# WKUP_UART0 register map
Vendor: Texas Instruments
Peripheral module from a debugger description file (folder J722S).
Registers are 32-bit, access per field, reset 0x0 unless marked. A register's access mark holds for its fields unless they carry their own. Offsets are as the file gives them; lines under a group give offsets from that group; [hi:lo] are bit positions; {n}, {i} and the like mark numbered series; 'fields as' and 'values as' point back to an identical list; <NAME> marks a mode.

## WKUP_UART0
0x00 MEM_DLL rw — Divisor Latches Low Register
  [7:0] CLOCK_LSB — Used to store the 8-bit LSB divisor value
0x00 MEM_RHR ro — The receiver section consists of the receiver holding register (RHR) and the receiver shift register. The RHR is actually a 64-byte FIFO. The receiver shift register receives serial data from RX input. The data is converted to parallel data and moved to the RHR. If the FIFO is disabled location zero of the FIFO is used to store the single data character. Note: If an overflow occurs the data in the RHR is not overwritten.
  [7:0] RHR — Receive holding register
0x00 MEM_THR — The transmitter section consists of the transmit holding register (THR) and the transmit shift register. The transmit holding register is actually a 64-byte FIFO. The LH writes data to the THR. The data is placed into the transmit shift register where it is shifted out serially on the TX output. If the FIFO is disabled location zero of the FIFO is used to store the data.
  [7:0] THR wo — TRANSMIT HOLDING REGISTER
0x04 MEM_DLH rw — Divisor Latches High Register
  [7:0] CLOCK_MSB — Used to store the 8-bit MSB divisor value
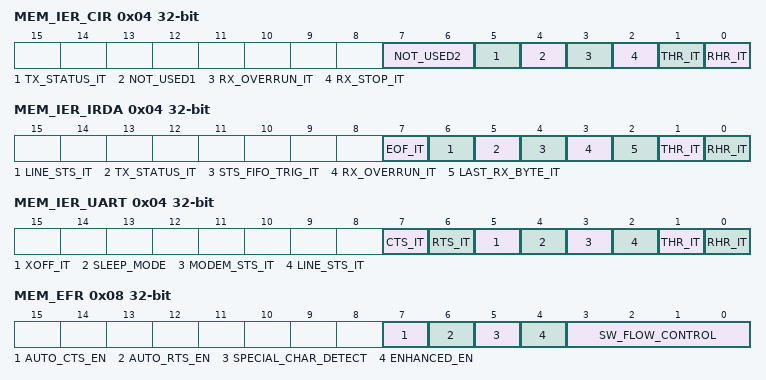
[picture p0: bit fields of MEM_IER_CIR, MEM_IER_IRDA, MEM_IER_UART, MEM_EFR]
0x04 MEM_IER_CIR rw — The interrupt enable register (IER) can be programmed to enable/disable any interrupt. There are 6 types of interrupt in these modes, TX status, status FIFO interrupt, RX overrun, last byte in RX FIFO, THR interrupt and RHR interrupt and they can be enabled/disabled individually.
  [7:6] NOT_USED2, [5] TX_STATUS_IT, [4] NOT_USED1, [3] RX_OVERRUN_IT, [2] RX_STOP_IT, [1] THR_IT, [0] RHR_IT
0x04 MEM_IER_IRDA rw — The interrupt enable register (IER) can be programmed to enable/disable any interrupt. There are 8 types of interrupt in these modes, received EOF, LSR interrupt, TX status, status FIFO interrupt, RX overrun, last byte in RX FIFO, THR interrupt and RHR interrupt and they can be enabled/disabled individually.
  [7] EOF_IT, [6] LINE_STS_IT, [5] TX_STATUS_IT, [4] STS_FIFO_TRIG_IT, [3] RX_OVERRUN_IT, [2] LAST_RX_BYTE_IT, [1] THR_IT, [0] RHR_IT
0x04 MEM_IER_UART — The interrupt enable register (IER) can be programmed to enable/disable any interrupt. There are seven types of interrupt in this mode: receiver error, RHR interrupt, THR interrupt, XOFF received and CTS*/RTS* change of state from low to high. Each interrupt can be enabled/disabled individually. There is also a sleep mode enable bit.
  [7] CTS_IT rw, [6] RTS_IT rw, [5] XOFF_IT rw, [4] SLEEP_MODE rw, [3] MODEM_STS_IT rw, [2] LINE_STS_IT rw, [1] THR_IT rw, [0] RHR_IT rw
0x08 MEM_EFR rw — Enhanced Feature Register
  [7] AUTO_CTS_EN — Auto-CTS enable bit. 0: Normal operation. 1: Auto-CTS flow control is enabled i.e. transmission is halted when the CTS* pin is high (inactive).
  [6] AUTO_RTS_EN — Auto-RTS enable bit. 0: Normal operation. 1: Auto- RTS flow control is enabled i.e. RTS* pin goes high (inactive) when the receiver FIFO HALT trigger level, TCR[3:0], is reached, and goes low (active) when the receiver FIFO RESTORE transmission trigger level is reached.
  [5] SPECIAL_CHAR_DETECT — 0: Normal operation. 1: Special character detect enable. Received data is compared with XOFF2 data. If a match occurs the received data is transferred to RX FIFO and IIR bit 4 is set to 1 to indicate a special character has been detected.
  [4] ENHANCED_EN — Enhanced functions write enable bit. 0: Disables writing to IER bits 4-7, FCR bits 4-5, and MCR bits 5-7. 1: Enables writing to IER bits 4-7, FCR bits 4-5, and MCR bits 5-7.
  [3:0] SW_FLOW_CONTROL — Combinations of Software flow control can be selected by programming bit 3 - bit 0. See Software Flow Control Options
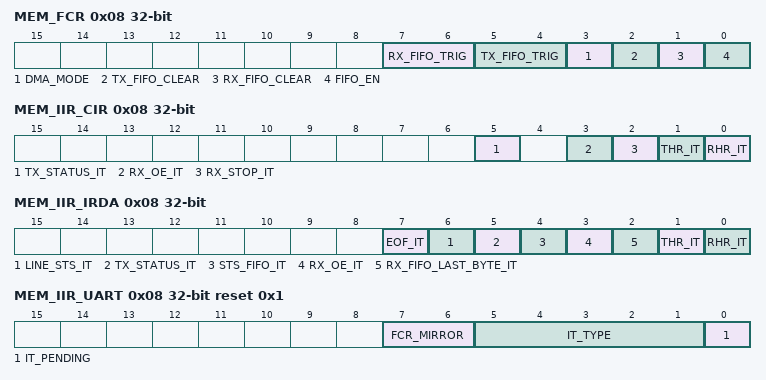
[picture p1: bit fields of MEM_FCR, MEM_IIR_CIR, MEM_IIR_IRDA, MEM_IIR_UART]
0x08 MEM_FCR — Notes: Bits 4 and 5 can only be written to when EFR[4] = 1 Bits 0 to 3 can be changed only when the baud clock is not running (DLL and DLH set to 0) See Table 31 for FCR[5:4] setting restriction when SCR[6]=1 See Table 32 for FCR[7:6] setting restriction when SCR[7]=1
  [7:6] RX_FIFO_TRIG wo — Sets the trigger level for the RX FIFO: If SCR[7] = 0 and TLR[7:4] = 0000: 00: 8 characters 01: 16 characters 10: 56 characters 11: 60 characters If SCR[7] = 0 and TLR[7:4] != 0000, RX_FIFO_TRIG is not considered. If SCR[7]=1, RX_FIFO_TRIG is 2 LSB of the trigger level [1-63 on 6 bits] with the granularity 1.
  [5:4] TX_FIFO_TRIG wo — Sets the trigger level for the TX FIFO: If SCR[6] = 0 and TLR[3:0] = 0000: 00: 8 spaces 01: 16 spaces 10: 32 spaces 11: 56 spaces If SCR[6] = 0 and TLR[3:0] != 0000, TX_FIFO_TRIG is not considered. If SCR[6]=1, TX_FIFO_TRIG is 2 LSB of the trigger level [1-63 on 6 bits] with the granularity 1
  [3] DMA_MODE wo — This register is considered if SCR[0] = 0.
  [2] TX_FIFO_CLEAR wo
  [1] RX_FIFO_CLEAR wo
  [0] FIFO_EN wo
0x08 MEM_IIR_CIR ro — The IIR is a read-only register, which provides the source of the interrupt in a prioritized manner.
  [5] TX_STATUS_IT, [3] RX_OE_IT, [2] RX_STOP_IT, [1] THR_IT, [0] RHR_IT
0x08 MEM_IIR_IRDA ro — The IIR is a read-only register, which provides the source of the interrupt in a prioritized manner.
  [7] EOF_IT, [6] LINE_STS_IT, [5] TX_STATUS_IT, [4] STS_FIFO_IT, [3] RX_OE_IT, [2] RX_FIFO_LAST_BYTE_IT, [1] THR_IT, [0] RHR_IT
0x08 MEM_IIR_UART ro reset 0x1 — The IIR is a read-only register, which provides the source of the interrupt in a prioritized manner.
  [7:6] FCR_MIRROR — Mirror the contents of FCR[0] on both bits.
  [5:1] IT_TYPE
  [0] IT_PENDING
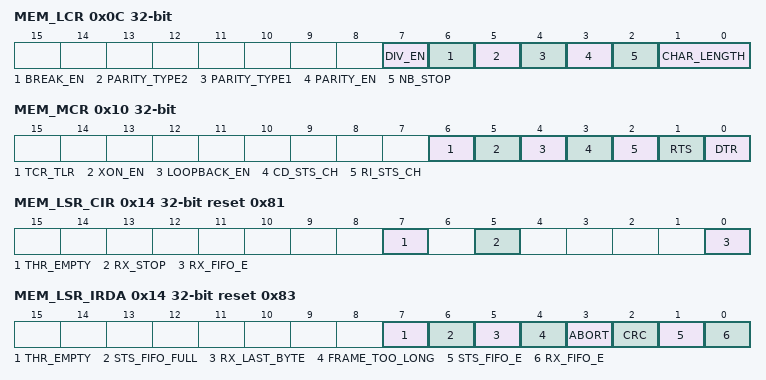
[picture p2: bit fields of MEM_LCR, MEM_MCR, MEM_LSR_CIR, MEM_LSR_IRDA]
0x0C MEM_LCR — LCR[6:0] define parameters of the transmission and reception. Note: As soon as LCR[6] is set to 1, the TX line is forced to 0 and remains in this state as long as LCR[6] = 1.
  [7] DIV_EN rw
  [6] BREAK_EN rw — Break control bit.
  [5] PARITY_TYPE2 rw — Selects the forced parity format [if LCR[3] = 1]. If LCR[5] = 1 and LCR[4] = 0, the parity bit is forced to 1 in the transmitted and received data. If LCR[5] = 1 and LCR[4] = 1, the parity bit is forced to 0 in the transmitted and received data.
  [4] PARITY_TYPE1 rw
  [3] PARITY_EN rw
  [2] NB_STOP rw — Specifies the number of stop bits:
  [1:0] CHAR_LENGTH rw — Specifies the word length to be transmitted or received.
0x10 MEM_MCR — MCR[3:0] controls the interface with the modem, data set or peripheral device that is emulating the modem.
  [6] TCR_TLR rw
  [5] XON_EN rw
  [4] LOOPBACK_EN rw
  [3] CD_STS_CH rw
  [2] RI_STS_CH rw
  [1] RTS rw — In loop back controls MSR[4]. If auto-RTS is enabled the RTS* output is controlled by hardware flow control.
  [0] DTR rw
0x10 MEM_XON1_ADDR1 rw — XON1/ADDR1 Register
  [7:0] XON_WORD1 — Used to store the 8-bit XON1 character in UART modes and ADDR1 address 1 for IrDA modes.
0x14 MEM_LSR_CIR ro reset 0x81
  [7] THR_EMPTY
  [5] RX_STOP — The RX_STOP is generated based on the value set in the BOF Length register (EBLR). It is cleared on a single read of the LSR register
  [0] RX_FIFO_E
0x14 MEM_LSR_IRDA ro reset 0x83
  [7] THR_EMPTY, [6] STS_FIFO_FULL, [5] RX_LAST_BYTE, [4] FRAME_TOO_LONG, [3] ABORT, [2] CRC, [1] STS_FIFO_E, [0] RX_FIFO_E
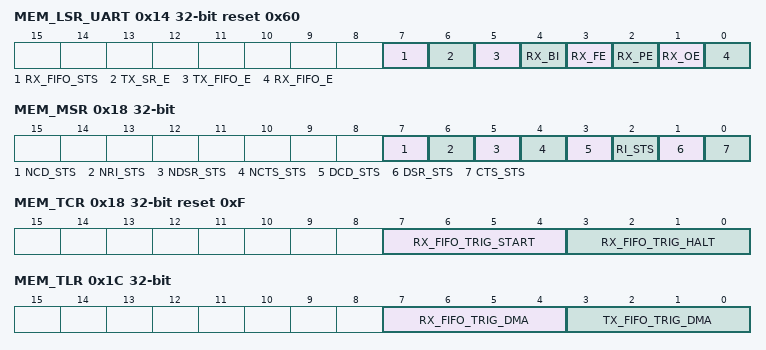
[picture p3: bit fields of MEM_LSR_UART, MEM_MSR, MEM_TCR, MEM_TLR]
0x14 MEM_LSR_UART ro reset 0x60
  [7] RX_FIFO_STS, [6] TX_SR_E, [5] TX_FIFO_E, [4] RX_BI, [3] RX_FE, [2] RX_PE, [1] RX_OE, [0] RX_FIFO_E
0x14 MEM_XON2_ADDR2 rw — XON2/ADDR2 Register
  [7:0] XON_WORD2 — Used to store the 8-bit XON2 character in UART modes and ADDR2 address 2 for IrDA modes.
0x18 MEM_MSR ro — This register provides information about the current state of the control lines from the modem, data set or peripheral device to the LH. It also indicates when a control input from the modem changes state.
  [7] NCD_STS — This bit is the complement of the DCD* input. In loop-back mode it is equivalent to MCR[3]
  [6] NRI_STS — This bit is the complement of the RI* input. In loop-back mode it is equivalent to MCR[2]
  [5] NDSR_STS — This bit is the complement of the DSR* input. In loop-back mode, it is equivalent to MCR[0]
  [4] NCTS_STS — This bit is the complement of the CTS* input. In loop-back mode it is equivalent to MCR[1]
  [3] DCD_STS — Indicates that DCD* input [or MCR[3] in loop back] has changed. Cleared on a read.
  [2] RI_STS — Indicates that RI* input [or MCR[2] in loop back] has changed state from low to high. Cleared on a read.
  [1] DSR_STS
  [0] CTS_STS
0x18 MEM_TCR rw reset 0xF — Transmission Control Register
  [7:4] RX_FIFO_TRIG_START — RX FIFO trigger level to RESTORE transmission (0 - 60)
  [3:0] RX_FIFO_TRIG_HALT — RX FIFO trigger level to HALT transmission (0 - 60)
0x18 MEM_XOFF1 rw — XOFF1 Register
  [7:0] XOFF_WORD1 — Used to store the 8-bit XOFF1 character in used in UART modes.
0x1C MEM_SPR — This read/write register does not control the module in anyway. It is intended as a scratchpad register to be used by the programmer to hold temporary data.
  [7:0] SPR_WORD rw — Scratchpad register
0x1C MEM_TLR rw — Trigger Level Register
  [7:4] RX_FIFO_TRIG_DMA — Receive FIFO trigger level
  [3:0] TX_FIFO_TRIG_DMA — Transmit FIFO trigger level
0x1C MEM_XOFF2 rw — XOFF2 Register
  [7:0] XOFF_WORD2 — Used to store the 8-bit XOFF2 character in used in UART modes.
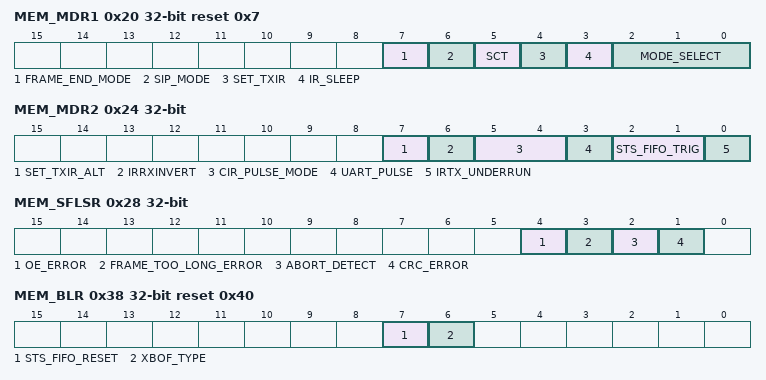
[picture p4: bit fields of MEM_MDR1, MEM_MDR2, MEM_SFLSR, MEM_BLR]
0x20 MEM_MDR1 reset 0x7 — The mode of operation can be programmed by writing to MDR1[2:0] and therefore the MDR1 must be programmed on start-up after configuration of the configuration registers (DLL, DLH, LCR). The value of MDR1[2:0] must not be changed again during normal operation. Note: If the module is disabled by setting the MODE_SELECT field to
  [7] FRAME_END_MODE rw — IrDA mode only.
  [6] SIP_MODE rw — MIR/FIR modes only.
  [5] SCT rw — Store and control the transmission
  [4] SET_TXIR rw — Used to configure the infrared transceiver.
  [3] IR_SLEEP rw
  [2:0] MODE_SELECT rw
0x24 MEM_MDR2 — IR-IrDA and IR-CIR modes only. MDR2[0] describes the status of the interrupt in IIR[5]. The IRTX_UNDERRUN bit should be read after an IIR[5] TX_STATUS_IT interrupt has occurred. The bits [2:1] of this register sets the trigger level for the frame status FIFO (8 entries) and must be programmed before the mode is programmed in MDR1[2:0]. Note: The MDR2[6] gives the flexibility to invert the RX pin inside the UART module to ensure that the protocol at the input of the transceiver module has the same polarity at module level. By default, the RX pin is inverted because most of transceiver invert the IR receive pin.
  [7] SET_TXIR_ALT rw — Provide alternate functionnality for MDR1[4] [SET_TXIR]
  [6] IRRXINVERT rw — Only for IR mode [IRDA & CIR]Invert RX pin inside the module before the voting or sampling system logic of the infra red block. This will not affect the RX path in UART Modem modes.
  [5:4] CIR_PULSE_MODE rw — CIR Pulse modulation definition. It defines high level of the pulse width associated with a digit:
  [3] UART_PULSE rw — UART mode only. Used to allow pulse shaping in UART mode.
  [2:1] STS_FIFO_TRIG rw — Only for IR-IRDA mode. Frame Status FIFO Threshold select:
  [0] IRTX_UNDERRUN ro — IRDA Transmission status interrupt.When the IIR[5] interrupt occurs, the meaning of the interrupt is :
0x28 MEM_SFLSR ro — IrDA modes only. Reading this register effectively reads frame status information from the status FIFO (this register doesn't physically exist). Reading this register will increment the status FIFO read pointer (SFREGL and SFREGH must be read first).
  [4] OE_ERROR, [3] FRAME_TOO_LONG_ERROR, [2] ABORT_DETECT, [1] CRC_ERROR
0x28 MEM_TXFLL — IrDA modes only. The registers TXFLL and TXFLH hold the 13-bit transmit frame length (expressed in bytes). TXFLL holds the least significant bits and TXFLH holds the most significant bits. The frame length value is used if the frame length method of frame closing is used.
  [7:0] TXFLL wo — LSB register used to specify the frame length
0x2C MEM_RESUME ro — IR-IrDA and IR-CIR modes only. This register is used to clear internal flags, which halt transmission/reception when an underrun/overrun error occurs. Reading this register resumes the halted operation. This register does not physically exist and reads always as 0x00.
  [7:0] RESUME — Dummy read to restart the TX or RX
0x2C MEM_TXFLH — IrDA modes only. The registers TXFLL and TXFLH hold the 13-bit transmit frame length (expressed in bytes). TXFLL holds the least significant bits and TXFLH holds the most significant bits. The frame length value is used if the frame length method of frame closing is used.
  [4:0] TXFLH wo — MSB register used to specify the frame length
0x30 MEM_RXFLL — IrDA modes only. The registers RXFLL and RXFLH hold the 12-bit receive maximum frame length. RXFLL holds the least significant bits and RXFLH holds the most significant bits. If the intended maximum receive frame length is n bytes, then program RXFLL and RXFLH to be n + 3 in SIR or MIR modes and n + 6 in FIR mode (+3 and +6 are due to frame format with CRC and stop flag; there are two bytes associated with the FIR stop flag).
  [7:0] RXFLL wo — LSB register used to specify the frame length in reception
0x30 MEM_SFREGL ro — IrDA modes only. The frame lengths of received frames are written into the status FIFO. This information can be read by reading the SFREGL and SFREGH registers (i.e. these registers do not physically exist). The least significant bits are read from SFREGL and the most significant bits are read from SFREGH. Reading these registers does not alter the status FIFO read pointer. These registers should be read before the pointer is incremented by reading the SFLSR.
  [7:0] SFREGL — LSB part of the frame length
0x34 MEM_RXFLH — IrDA modes only. The registers RXFLL and RXFLH hold the 12-bit receive maximum frame length. RXFLL holds the least significant bits and RXFLH holds the most significant bits. If the intended maximum receive frame length is n bytes, then program RXFLL and RXFLH to be n + 3 in SIR or MIR modes and n + 6 in FIR mode (+3 and +6 are due to frame format with CRC and stop flag; there are two bytes associated with the FIR stop flag).
  [3:0] RXFLH wo — MSB register used to specify the frame length in reception
0x34 MEM_SFREGH ro — IrDA modes only. The frame lengths of received frames are written into the status FIFO. This information can be read by reading the SFREGL and SFREGH registers (i.e. these registers do not physically exist). The least significant bits are read from SFREGL and the most significant bits are read from SFREGH. Reading these registers does not alter the status FIFO read pointer. These registers should be read before the pointer is incremented by reading the SFLSR.
  [3:0] SFREGH — MSB part of the frame length
0x38 MEM_BLR access not given reset 0x40 — IrDA modes only. Note that BLR[6] is used to select whether 0xC0 or 0xFF start patterns are to be used, when multiple start flags are required in SIR Mode. If only one start flag is required, this will always be 0xC0. If n start flags are required, then either (n-1) 0xC0 or (n-1) 0xFF flags are sent, followed by a single 0xC0 flag (immediately preceding the first data byte).
  [7] STS_FIFO_RESET — Status FIFO reset. This bit is self-clearing (access R/W1TS)
  [6] XBOF_TYPE rw — SIR xBOF select.
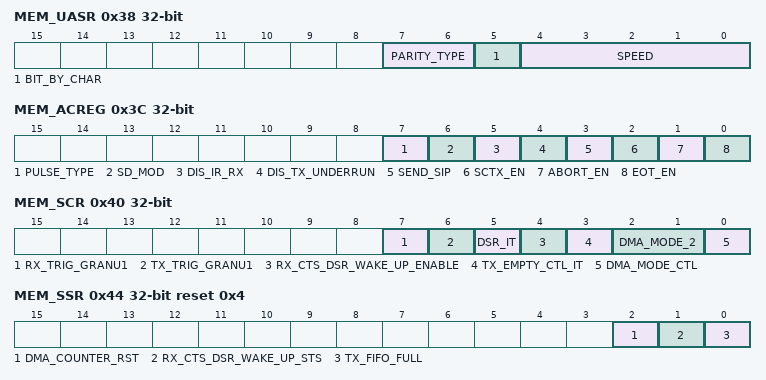
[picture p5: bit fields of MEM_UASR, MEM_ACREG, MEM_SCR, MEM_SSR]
0x38 MEM_UASR ro — UART Autobauding Status Register
  [7:6] PARITY_TYPE — 00 => No Parity identified. 01 => Parity space. 10 => Even Parity. 11 => Odd Parity
  [5] BIT_BY_CHAR — 0 => 7 bits character identified. 1 => 8 bits character identified
  [4:0] SPEED — Used to report the speed identified. 00000 => No speed identified. 00001 => 115200 bauds. 00010 => 57600 bauds. 00011 => 38400 bauds. 00100 => 28800 bauds. 00101 => 19200 bauds. 00110 => 14400 bauds. 00111 => 9600 bauds. 01000 => 4800 bauds. 01001 => 2400 bauds. 01010 => 1200 bauds
0x3C MEM_ACREG access not given — IR-IrDA and IR-CIR modes only.
  [7] PULSE_TYPE rw — SIR pulse width select:
  [6] SD_MOD rw — Primary output used to configure transceivers. Connected to the SD/MODE input pin of IrDA transceivers.
  [5] DIS_IR_RX rw
  [4] DIS_TX_UNDERRUN rw — It is recommended to disable TX FIFO underrun capability by masking corresponding underrun interrupt. When disabling underrun by setting ACREG[4]=1, garbage data is sent over TX line.
  [3] SEND_SIP — MIR/FIR Modes only.Send Serial Infrared Interaction Pulse [SIP] If this bit is set during a MIR/FIR transmission, the SIP will be send at the end of it.This bit automatically gets cleared at the end of the SIP transmission. (access R/W1TS)
  [2] SCTX_EN — Store and controlled TX start. When MDR1[5] = 1 and the LH writes 1 to this bit the TX state machine starts frame transmission. This bit is self-clearing. (access R/W1TS)
  [1] ABORT_EN rw — Frame Abort. The LH can intentionally abort transmission of a frame by writing 1 to this bit. Neither the end flag nor the CRC bits are appended to the frame. If transmit FIFO is not empty and MDR1[5]=1, UART IrDA will start a new transfer with data of previous frame as soon as abort frame has been sent. Therefore, TX FIFO must be reset before sending an abort frame.
  [0] EOT_EN — EOT [end of transmission] bit. The LH writes 1 to this bit just before it writes the last byte to the TX FIFO in set-EOT bit frame closing method. This bit automatically gets cleared when the LH writes to the THR [TX FIFO]. (access R/W1TS)
0x40 MEM_SCR — Note: Bit 4 enables the wake-up interrupt, but this interrupt is not mapped into the IIR register. Therefore, when an interrupt occurs and there is no interrupt pending in the IIR register, the SSR[1] bit must be checked. To clear the wake-up interrupt, bit SCR[4] must be reset to 0.
  [7] RX_TRIG_GRANU1 rw
  [6] TX_TRIG_GRANU1 rw
  [5] DSR_IT rw
  [4] RX_CTS_DSR_WAKE_UP_ENABLE rw
  [3] TX_EMPTY_CTL_IT rw
  [2:1] DMA_MODE_2 rw — Used to specify the DMA mode valid if SCR[0] = 1
  [0] DMA_MODE_CTL rw
0x44 MEM_SSR reset 0x4 — Note: Bit 1 is reset only when SCR[4] is reset to 0.
  [2] DMA_COUNTER_RST rw, [1] RX_CTS_DSR_WAKE_UP_STS ro, [0] TX_FIFO_FULL ro
0x48 MEM_EBLR — IR-IrDA and IR-CIR modes only. In IR-IrDA SIR operation, this register specifies the number of BOF + xBOFs to transmit. Value set into this register must take into account the BOF character, therefore to only sent one BOF with no XBOF this register must be set to 1. To send one BOF with N XBOF this register must be set to N+1. Furthermore, the value 0 will send 1 BOF plus 255 XBOF. In IR-IrDA MIR mode, this register specifies the number of additional start flags (MIR protocol mandates a minimum of 2 start flags). In IR-CIR mode, this register specifies the number of consecutive zeros to be received before generating the RX_STOP interrupt (IIR[2]). All the received zeros are stored in the RX FIFO. When the register is set to 0, this feature is de-activated and always in reception state which can be disabled by setting the ACREG[5] to
  [7:0] EBLR rw — IR-IRDA mode: This register allows to define up to 176 xBOFs, the maximum required by IrDA specification. IR-CIR mode: This register specifies the number of consecutive zeros to be received before generating the RX_STOP interrupt [IIR[2]]. 0x00: feature disabled. 0x01: generate RX_STOP interrupt after receiving one zero bit. ... 0xFF: generate RX_STOP interrupt after receiving 255 zero bits.
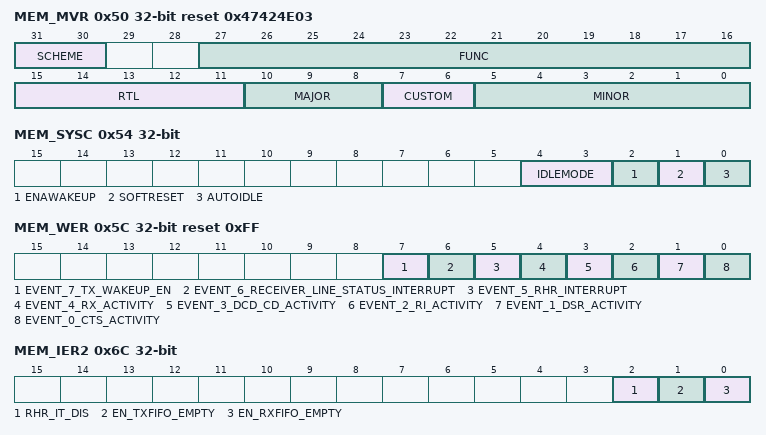
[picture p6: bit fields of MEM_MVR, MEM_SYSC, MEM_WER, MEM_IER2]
0x50 MEM_MVR ro reset 0x47424E03 — The reset value is fixed by hardware and corresponds to the RTL revision of this module. A reset has no effect on the value returned Notes: UART / IRDA SIR only module is revision 1.x (WMU_012_1 specification). UART / IRDA with SIR, MIR and FIR support is revision 2.x (WMU_012_2 specification). UART / IRDA with SIR, MIR and FIR / CIR support is revision 3.x (this specification). For example: MVR = 0x30 => Version 3.0 MVR = 0x38 => Version 3.8
  [31:30] SCHEME — Scheme revision number of module
  [27:16] FUNC — Function revision number of module
  [15:11] RTL — Rtl revision number of module
  [10:8] MAJOR — Major revision number of the module.
  [7:6] CUSTOM — Custom revision number of the module.
  [5:0] MINOR — Minor revision number of the module.
0x54 MEM_SYSC — The auto idle bit controls a power saving technique to reduce the logic power consumption of the OCP interface. That is to say when the feature is enabled, the clock will be gated off until an OCP command for this device has been detected. When the software reset bit is set high it causes a full device reset.
  [4:3] IDLEMODE rw — POWER MANAGEMENT REQ/ACK CONTROL REF: OCP DESIGN GUIDELINES VERSION 1.1
  [2] ENAWAKEUP rw — WAKE UP FEATURE CONTROL
  [1] SOFTRESET wo — Software reset. Set this bit to 1 to trigger a module reset. This bit is automatically reset by the hardware. During reads it always returns a 0.
  [0] AUTOIDLE rw — Internal OCP clock gating strategy
0x58 MEM_SYSS ro
  [0] RESETDONE — Internal Reset Monitoring
0x5C MEM_WER reset 0xFF — The UART wakeup enable register is used to mask and unmask a UART event that would subsequently notify the system. The events are any activity in the logic that could cause an interrupt and/ or an activity that would require the system to wakeup. It should be noted that even if the wakeup is disabled for certain events, if these events are also an interrupt to the UART, then the UART will still register the interrupt as such.
  [7] EVENT_7_TX_WAKEUP_EN rw, [6] EVENT_6_RECEIVER_LINE_STATUS_INTERRUPT rw, [5] EVENT_5_RHR_INTERRUPT rw, [4] EVENT_4_RX_ACTIVITY rw, [3] EVENT_3_DCD_CD_ACTIVITY rw, [2] EVENT_2_RI_ACTIVITY rw, [1] EVENT_1_DSR_ACTIVITY rw, [0] EVENT_0_CTS_ACTIVITY rw
0x60 MEM_CFPS reset 0x69 — Since the Consumer IR works at modulation rates of 30 56.8 KHz, the 48 MHz clock must be pre scaled before the clock can drive the IR logic. This register sets the divisor rate to give a range to accommodate the remote control requirements in BAUD multiples of 12x. The value of the CFPS at reset is 0105 decimal which equates to a 38.1 KHz output from starting conditions. The 48 MHz carrier is prescaled by the CFPS which is then divided by the 12x BAUD multiple.
  [7:0] CFPS rw — System clock frequency prescaler at [12x multiple]. Examples for CFPS values are given in the table below. Target Freq [KHz] CFPS [decimal] Actual Freq[KHz] 30 133 30.08 32.75 122 32.79 36 111 36.04 36.7 109 36.69 38* 105 38.1 40 100 40 56.8 70 57.14 * configured at reset to this value Note: CFPS = 0 is not supported.
0x64 MEM_RXFIFO_LVL ro — Level of the RX FIFO
  [7:0] RXFIFO_LVL
0x68 MEM_TXFIFO_LVL ro — Level of the TX FIFO
  [7:0] TXFIFO_LVL
0x6C MEM_IER2 — Enables RX/TX FIFOs empty corresponding interrupts.
  [2] RHR_IT_DIS rw
  [1] EN_TXFIFO_EMPTY rw — Enables[1]/DISABLES[00 EN_TXFIFO_EMPTY interrupt.
  [0] EN_RXFIFO_EMPTY rw — Enables[1]/disables[0] EN_RXFIFO_EMPTY interrupt.
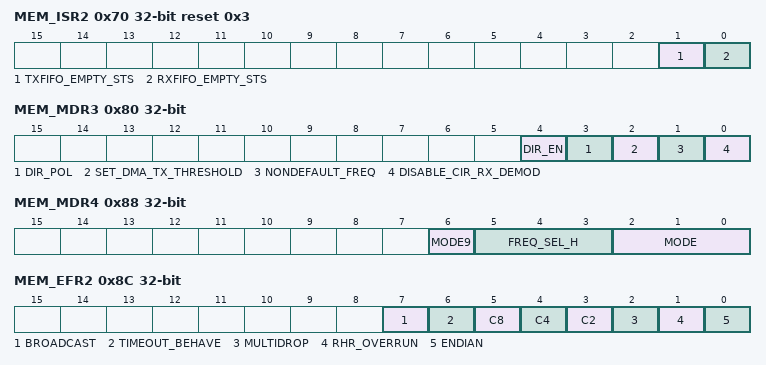
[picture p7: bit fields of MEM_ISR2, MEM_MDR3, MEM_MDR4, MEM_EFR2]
0x70 MEM_ISR2 access not given reset 0x3 — Status of RX/TX FIFOs empty corresponding interrupts.
  [1] TXFIFO_EMPTY_STS — TXFIFO interrupt pending (access R/W1TC)
  [0] RXFIFO_EMPTY_STS — RXFIFO interrupt pending (access R/W1TC)
0x74 MEM_FREQ_SEL rw reset 0x1A — Sample per bit value selector
  [7:0] FREQ_SEL — Sets the sample per bit if non default frequency is used. MDR3[1] must be set to 1 after this value is set. Must be equal or higher then 6.
0x78 MEM_ABAUD_1ST_CHAR ro — Unused
0x7C MEM_BAUD_2ND_CHAR ro — Unused
0x80 MEM_MDR3 — Mode definition register 3.
  [4] DIR_EN rw — RS-485 External Transceiver Direction Enable
  [3] DIR_POL rw — RS-485 External Transceiver Direction Polarity. 0 => TX: RTS=0, RX: RTS=1. 1 => TX: RTS=1, RX: RTS=0
  [2] SET_DMA_TX_THRESHOLD rw — Enable to set different TX DMA threshold then 64-trigger [usage of new register TX_DNA_THRESHOLD]
  [1] NONDEFAULT_FREQ rw — Enables[1]/Disables[0] using NONDEFAULT fclk frequencies
  [0] DISABLE_CIR_RX_DEMOD rw — Disables[1]/Enables[0] CIR RX demodulation
0x84 MEM_TX_DMA_THRESHOLD rw — Use to manually set the TX DMA threshold level. MDR3[2] SET_TX_DMA_THRESHOLD must be one and must be value + tx_trigger_level &#60;= 64 (TX FIFO size). If not, 64-tx_trigger_level will be used w/o modifying the value of this register.
  [5:0] TX_DMA_THRESHOLD — Use to manually set the TX DMA threshold level.
0x88 MEM_MDR4 — Mode definition register 4
  [6] MODE9 rw — 9-bit character length. When '1', overrides character length setting in LCR
  [5:3] FREQ_SEL_H rw — Upper 3 bits of FREQ_SEL register for higher division values, as required for example for FI/Di in ISO7816 mode
  [2:0] MODE rw — New modes [when set, overrides MDR1 modes]
0x8C MEM_EFR2 — Enhanced Features Register 2
  [7] BROADCAST rw — Enables broadcast address matching in multi-drop address match mode
  [6] TIMEOUT_BEHAVE rw — Specifies how timeout is measured
  [5] C8 rw — Value for ISO 7816 C8 pin for software control
  [4] C4 rw — Value for ISO 7816 C4 pin for software control
  [3] C2 rw — Value for ISO 7816 reset pin [software controllable]
  [2] MULTIDROP rw — Enables parity Multi-drop mode [overrides LCR[5..3]] when '1'
  [1] RHR_OVERRUN rw — RHR Overrun behaviour when buffer full
  [0] ENDIAN rw — Endianness
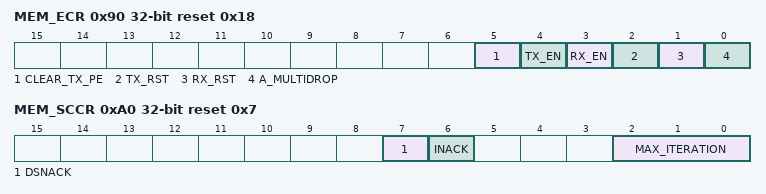
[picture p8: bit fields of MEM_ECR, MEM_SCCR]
0x90 MEM_ECR reset 0x18 — Enhanced Control register
  [5] CLEAR_TX_PE wo — Write 1 to clear parity error from the Transmitter to allow it to continue to try sending data [ISO7816 transmit only]
  [4] TX_EN rw — Enables/Disables the transmitter
  [3] RX_EN rw — Enables/Disables the receiver
  [2] TX_RST wo — Writing '1' resets the transmitter
  [1] RX_RST wo — Writing '1' resets the receiver
  [0] A_MULTIDROP wo — In multi-drop mode, when written with the value '1' causes the next byte written into THR to be transmitted with the parity bit set, signaling an address
0x94 MEM_TIMEGUARD — Timeguard
  [7:0] TIMEGUARD rw — Specifies the amount of idle baud clocks [transmitter bit period] to insert between transmitted bytes, useful when comunicating with slower devices
0x98 MEM_TIMEOUTL — Timeout lower byte
  [7:0] TIMEOUT_L rw — Custom timeout period in baud clocks, to override the internal value, when different from 0. [Lower byte of the 16 bit value]
0x9C MEM_TIMEOUTH — Timeout higher byte
  [7:0] TIMEOUT_H rw — Custom timeout period in baud clocks, to override the internal value, when different from 0. [Higher byte of the 16 bit value]
0xA0 MEM_SCCR reset 0x7 — Smartcard (ISO7816) mode Control Register
  [7] DSNACK rw — Applies Max_Iteration to receiver aswell - when maximum number of NACKs have been returned, the receiver will accept the data regardless of error. The data will be loaded into the receiver FIFO and PE will be set when reading it.
  [6] INACK rw — Inhibit NACK when receiving, even if an error is received. The data will be loaded into the receiver FIFO and PE will be set when reading it.
  [2:0] MAX_ITERATION rw — Number of times to repeat transmitted character, if the receiver did not acknowledge. If not acknowledged after the max value is reached, the USART transmitter will set parity error, stop and not continue until it is cleared.
0xA4 MEM_ERHR ro — Extended Receive Holding Register
  [8:0] ERHR — Extended Receive Holding Register - allows accessing the full 9bit RHR
0xA4 MEM_ETHR — Extended Transmit Holding Register
  [8:0] ETHR wo — Extended Transmit Holding Register - allows writing the full 9bit RHR
0xA8 MEM_MAR rw — Multidrop Address Register
  [7:0] ADDRESS — Multidrop match address value
0xAC MEM_MMR rw — Multidrop Mask Register
  [7:0] MASK — Address match masking value ? writing a 0 to a bit means that the corresponding address bit will be ignored in matching
0xB0 MEM_MBR rw — Multidrop Broadcast Address Register
  [7:0] BROADCAST_ADDRESS — Broadcast address for address matching
